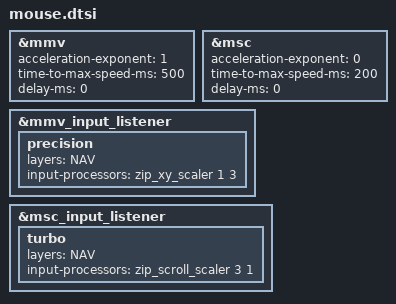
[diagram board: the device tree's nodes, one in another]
// This file was adapted from caksoylar's and urob's repos on GitHub

// Add these lines to your .conf file
// # Mouse config
// CONFIG_ZMK_MOUSE=y
// CONFIG_ZMK_POINTING_SMOOTH_SCROLLING=y

// Add the bellow lines to your .keymap file
//
// Include and layer definition
// #define MOU 5
// #include "mouse.dtsi"

// Settings tuned up for 3840 x 2160 display resolution
#define ZMK_POINTING_DEFAULT_MOVE_VAL 1500 // 600
#define ZMK_POINTING_DEFAULT_SCRL_VAL 20  // 10

#include <dt-bindings/zmk/mouse.h>
#include <dt-bindings/zmk/pointing.h>
#include <input/processors.dtsi>

// Based on @caksoylar's config, defaults in comments
&mmv {
  acceleration-exponent = <1>;          // 1
  time-to-max-speed-ms = <500>;         // 300
  delay-ms = <0>;                       // 0
};

&msc {
  acceleration-exponent = <0>;          // 0
  time-to-max-speed-ms = <200>;         // 300
  delay-ms = <0>;                       // 0
};

&mmv_input_listener {
    precision {
        layers = <NAV>;
        input-processors = <&zip_xy_scaler 1 3>;
    };
};

&msc_input_listener {
    turbo {
        layers = <NAV>;
        input-processors = <&zip_scroll_scaler 3 1>;
    };
};
